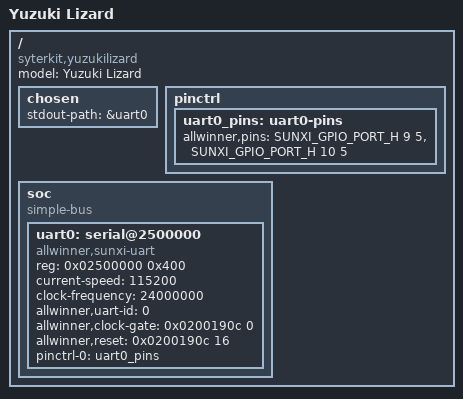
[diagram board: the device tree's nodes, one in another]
// SPDX-License-Identifier: GPL-2.0+
/dts-v1/;

#include <dt-bindings/gpio/sunxi-gpio.h>

/ {
	#address-cells = <1>;
	#size-cells = <1>;
	model = "Yuzuki Lizard";
	compatible = "syterkit,yuzukilizard";

	chosen {
		stdout-path = &uart0;
	};

	pinctrl {
		uart0_pins: uart0-pins {
			allwinner,pins =
				<SUNXI_GPIO_PORT_H 9 5>,
				<SUNXI_GPIO_PORT_H 10 5>;
		};
	};

	soc {
		compatible = "simple-bus";
		#address-cells = <1>;
		#size-cells = <1>;
		ranges;

		uart0: serial@2500000 {
			compatible = "allwinner,sunxi-uart";
			reg = <0x02500000 0x400>;
			current-speed = <115200>;
			clock-frequency = <24000000>;
			allwinner,uart-id = <0>;
			allwinner,clock-gate = <0x0200190c 0>;
			allwinner,reset = <0x0200190c 16>;
			pinctrl-names = "default";
			pinctrl-0 = <&uart0_pins>;
			status = "okay";
		};
	};
};
